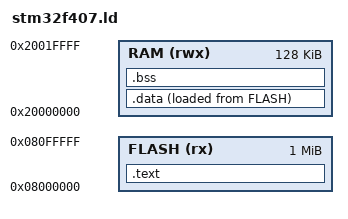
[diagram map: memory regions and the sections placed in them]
/* STM32F407VG Linker Script */

ENTRY(Reset_Handler)

MEMORY
{
    FLASH (rx) : ORIGIN = 0x08000000, LENGTH = 1024K
    RAM  (rwx) : ORIGIN = 0x20000000, LENGTH = 128K
}

_estack = ORIGIN(RAM) + LENGTH(RAM);

SECTIONS
{
    .text :
    {
        . = ALIGN(4);

        KEEP(*(.isr_vector))
        *(.text)
        *(.text*)
        *(.rodata)
        *(.rodata*)

        . = ALIGN(4);

        _etext = .;
    } > FLASH

    _sidata = LOADADDR(.data);
    
    .data :
    {
        . = ALIGN(4);

        _sdata = .;

        *(.data)
        *(.data*)

        . = ALIGN(4);
        
        _edata = .;

    } > RAM AT > FLASH

    .bss :
    {
        . = ALIGN(4);

        _sbss = .;

        *(.bss)
        *(.bss*)
        *(COMMON)

        . = ALIGN(4);

        _ebss = .;

    } > RAM

    . = ALIGN(4);
    _end = .;
}
